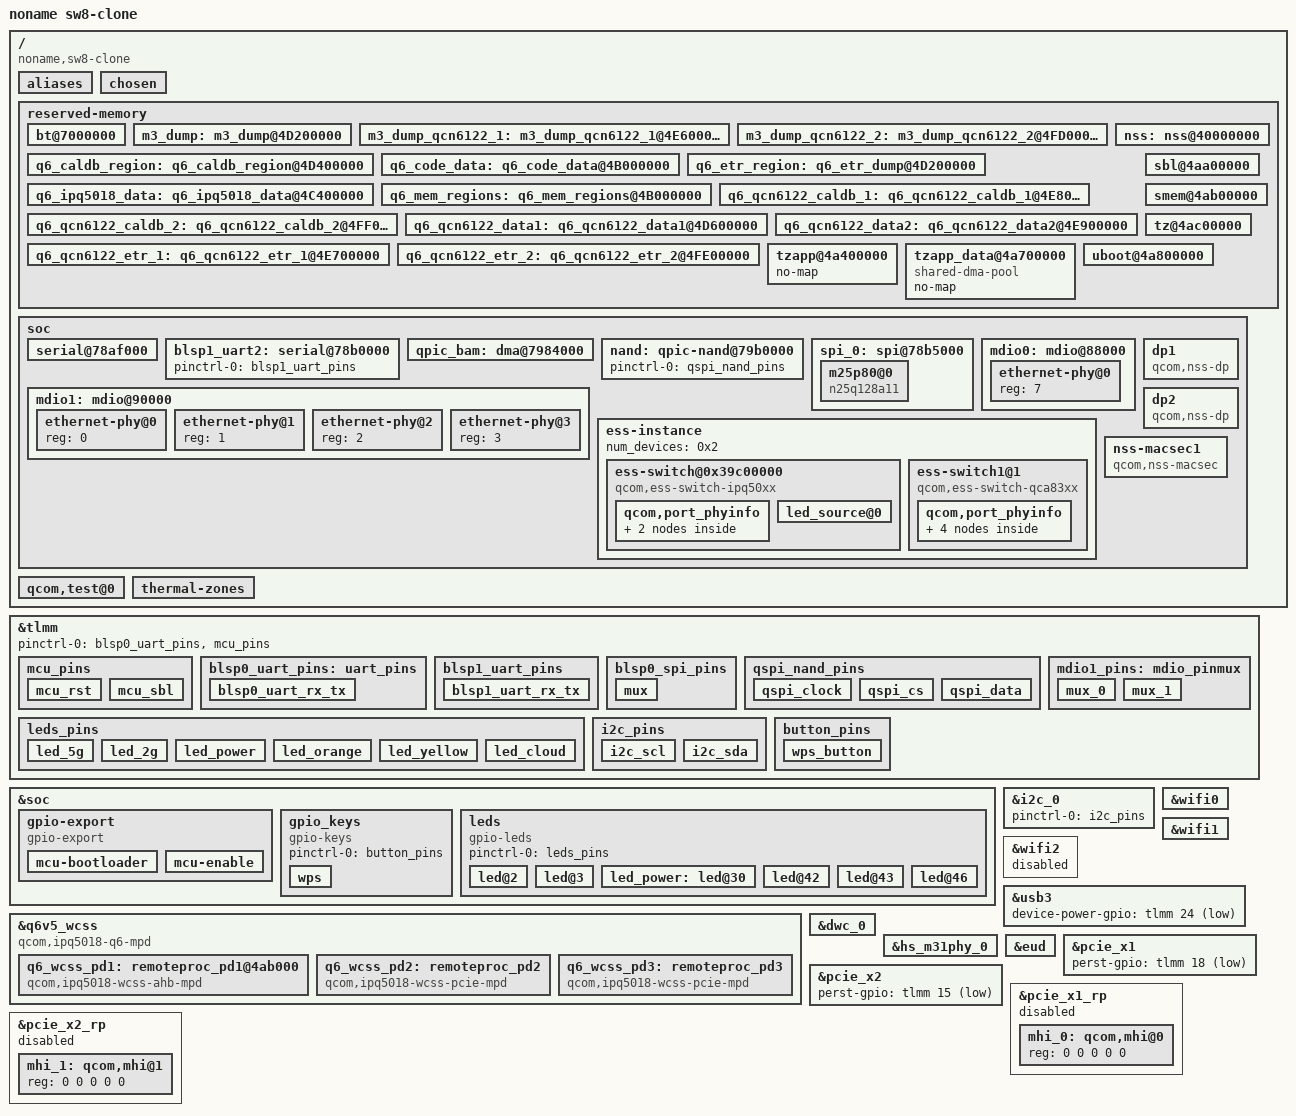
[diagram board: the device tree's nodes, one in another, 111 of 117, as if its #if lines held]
/dts-v1/;

#include "ipq5018.dtsi"
#include <dt-bindings/input/input.h>

/ {
	#address-cells = <0x2>;
	#size-cells = <0x2>;
	model = "noname sw8-clone";
	compatible = "noname,sw8-clone", "qcom,ipq5018-mp03.5", "qcom,ipq5018";
	interrupt-parent = <&intc>;

	aliases {
		sdhc1 = &sdhc_1; /* SDC1 eMMC slot */
		serial0 = &blsp1_uart1;
		serial1 = &blsp1_uart2;
		ethernet0 = "/soc/dp1";
		ethernet1 = "/soc/dp2";

		led-boot = &led_power;
		led-failsafe = &led_power;
		led-running = &led_power;
		led-upgrade = &led_power;
	};

	chosen {
		bootargs = "console=ttyMSM0,115200,n8 rw init=/init";
		bootargs-append = " root=/dev/ubiblock0_1 swiotlb=1 coherent_pool=2M";
		stdout-path = "serial0";
	};

	reserved-memory {
		#address-cells = <0x02>;
		#size-cells = <0x02>;
		ranges;

		bt@7000000 {
			no-map;
			reg = <0x00 0x7000000 0x00 0x58000>;
		};

		m3_dump: m3_dump@4D200000 {
			no-map;
			reg = <0x00 0x4d200000 0x00 0x100000>;
		};

		m3_dump_qcn6122_1: m3_dump_qcn6122_1@4E600000 {
			no-map;
			reg = <0x00 0x4e600000 0x00 0x100000>;
		};

		m3_dump_qcn6122_2: m3_dump_qcn6122_2@4FD00000 {
			no-map;
			reg = <0x00 0x4fd00000 0x00 0x100000>;
		};

		nss: nss@40000000 {
			no-map;
			reg = <0x00 0x40000000 0x00 0x1000000>;
		};

		q6_caldb_region: q6_caldb_region@4D400000 {
			no-map;
			reg = <0x00 0x4d400000 0x00 0x200000>;
		};

		q6_code_data: q6_code_data@4B000000 {
			no-map;
			reg = <0x00 0x4b000000 0x00 0x60000>;
		};

		q6_etr_region: q6_etr_dump@4D200000 {
			no-map;
			reg = <0x00 0x4d200000 0x00 0x100000>;
		};

		q6_ipq5018_data: q6_ipq5018_data@4C400000 {
			no-map;
			reg = <0x00 0x4c400000 0x00 0xd00000>;
		};

		q6_mem_regions: q6_mem_regions@4B000000 {
			no-map;
			reg = <0x00 0x4b000000 0x00 0x3400000>;
		};

		q6_qcn6122_caldb_1: q6_qcn6122_caldb_1@4E800000 {
			linux,phandle = <0x1c>;
			no-map;
			phandle = <0x1c>;
			reg = <0x00 0x4e800000 0x00 0x500000>;
		};

		q6_qcn6122_caldb_2: q6_qcn6122_caldb_2@4FF00000 {
			no-map;
			reg = <0x00 0x4ff00000 0x00 0x500000>;
		};

		q6_qcn6122_data1: q6_qcn6122_data1@4D600000 {
			linux,phandle = <0x19>;
			no-map;
			phandle = <0x19>;
			reg = <0x00 0x4d600000 0x00 0x1000000>;
		};

		q6_qcn6122_data2: q6_qcn6122_data2@4E900000 {
			no-map;
			reg = <0x00 0x4ed00000 0x00 0x1000000>;
		};

		q6_qcn6122_etr_1: q6_qcn6122_etr_1@4E700000 {
			linux,phandle = <0x1b>;
			no-map;
			phandle = <0x1b>;
			reg = <0x00 0x4e700000 0x00 0x100000>;
		};

		q6_qcn6122_etr_2: q6_qcn6122_etr_2@4FE00000 {
			no-map;
			reg = <0x00 0x4fe00000 0x00 0x100000>;
		};

		sbl@4aa00000 {
			no-map;
			reg = <0x00 0x4aa00000 0x00 0x100000>;
		};

		smem@4ab00000 {
			no-map;
			reg = <0x00 0x4ab00000 0x00 0x100000>;
		};

		tz@4ac00000 {
			no-map;
			reg = <0x00 0x4ac00000 0x00 0x400000>;
		};

		tzapp@4a400000 {
			no-map;
		};

		tzapp_data@4a700000 {
			compatible = "shared-dma-pool";
			no-map;
		};

		uboot@4a800000 {
			no-map;
			reg = <0x00 0x4a800000 0x00 0x200000>;
		};
	};

	soc {
		serial@78af000 {
			status = "ok";
		};

		blsp1_uart2: serial@78b0000 {
			pinctrl-0 = <&blsp1_uart_pins>;
			pinctrl-names = "default";
			status = "ok";
		};

		qpic_bam: dma@7984000{
			status = "ok";
		};

		nand: qpic-nand@79b0000 {
			pinctrl-0 = <&qspi_nand_pins>;
			pinctrl-names = "default";
			status = "ok";
		};

		spi_0: spi@78b5000 { /* BLSP1 QUP0 */
			pinctrl-0 = <&blsp0_spi_pins>;
			pinctrl-names = "default";
			cs-select = <0>;
			status = "ok";

			m25p80@0 {
				#address-cells = <1>;
				#size-cells = <1>;
				reg = <0>;
				compatible = "n25q128a11";
				linux,modalias = "m25p80", "n25q128a11";
				spi-max-frequency = <50000000>;
				use-default-sizes;
			};
		};

		mdio0: mdio@88000 {
			status = "ok";

			ethernet-phy@0 {
				reg = <7>;
			};
		};

		mdio1: mdio@90000 {
			status = "ok";
			pinctrl-0 = <&mdio1_pins>;
			pinctrl-names = "default";
			phy-reset-gpio = <&tlmm 39 0>;
			ethernet-phy@0 {
				reg = <0>;
			};

			ethernet-phy@1 {
				reg = <1>;
			};

			ethernet-phy@2 {
				reg = <2>;
			};

			ethernet-phy@3 {
				reg = <3>;
			};
		};

		ess-instance {
			num_devices = <0x2>;
			ess-switch@0x39c00000 {
				compatible = "qcom,ess-switch-ipq50xx";
				device_id = <0>;
				switch_mac_mode = <0xf>; /* mac mode for uniphy instance*/
				cmnblk_clk = "internal_96MHz"; /* cmnblk clk*/
				qcom,port_phyinfo {
					port@0 {
						port_id = <1>;
						phy_address = <7>;
					};
					port@1 {
						port_id = <2>;
						forced-speed = <1000>;
						forced-duplex = <1>;
					};
				};
				led_source@0 {
					source = <0>;
					mode = "normal";
					speed = "all";
					blink_en = "enable";
					active = "high";
				};
			};
			ess-switch1@1 {
				compatible = "qcom,ess-switch-qca83xx";
				device_id = <1>;
				switch_access_mode = "mdio";
				mdio-bus = <&mdio1>;
				reset_gpio = <&tlmm 0x27 0>;
				switch_cpu_bmp = <0x40>;  /* cpu port bitmap */
				switch_lan_bmp = <0x1e>; /* lan port bitmap */
				switch_wan_bmp = <0x0>;  /* wan port bitmap */
				qca,ar8327-initvals = <
						0x00004 0x7600000   /* PAD0_MODE */
						0x00008 0x1000000   /* PAD5_MODE */
						0x0000c 0x80	/* PAD6_MODE */
						0x00010 0x2613a0    /* PORT6 FORCE MODE*/
						0x000e4 0xaa545     /* MAC_POWER_SEL */
						0x000e0 0xc74164de  /* SGMII_CTRL */
						0x0007c 0x4e	/* PORT0_STATUS */
						0x00094 0x4e	/* PORT6_STATUS */
				>;
				qcom,port_phyinfo {
					port@0 {
						port_id = <1>;
						phy_address = <0>;
					};
					port@1 {
						port_id = <2>;
						phy_address = <1>;
					};
					port@2 {
						port_id = <3>;
						phy_address = <2>;
					};
					port@3 {
						port_id = <4>;
						phy_address = <3>;
					};
				};
			};
		};

		dp1 {
			device_type = "network";
			compatible = "qcom,nss-dp";
			clocks = <&gcc GCC_SNOC_GMAC0_AXI_CLK>;
			clock-names = "nss-snoc-gmac-axi-clk";
			qcom,id = <1>;
			reg = <0x39C00000 0x10000>;
			interrupts = <GIC_SPI 101 IRQ_TYPE_LEVEL_HIGH>;
			qcom,mactype = <2>;
			qcom,link-poll = <1>;
			qcom,phy-mdio-addr = <7>;
			mdio-bus = <&mdio0>;
			local-mac-address = [000000000000];
			phy-mode = "sgmii";
			qcom,rx-page-mode = <0>;
		};

		dp2 {
			device_type = "network";
			compatible = "qcom,nss-dp";
			clocks = <&gcc GCC_SNOC_GMAC1_AXI_CLK>;
			clock-names = "nss-snoc-gmac-axi-clk";
			qcom,id = <2>;
			reg = <0x39D00000 0x10000>;
			interrupts = <GIC_SPI 109 IRQ_TYPE_LEVEL_HIGH>;
			qcom,mactype = <2>;
			local-mac-address = [000000000000];
			phy-mode = "sgmii";
			qcom,rx-page-mode = <0>;
		};

		nss-macsec1 {
			compatible = "qcom,nss-macsec";
			phy_addr = <0x1c>;
			mdiobus = <&mdio1>;
		};
	};

	qcom,test@0 {
		status = "ok";
	};

	thermal-zones {
		status = "ok";
	};
};

&tlmm {
	pinctrl-0 = <&blsp0_uart_pins &mcu_pins>;
	pinctrl-names = "default";

	mcu_pins: mcu_pins {
		mcu_rst {
			pins = "gpio31";
			function = "gpio";
			drive-strength = <8>;
			bias-disable;
			output-low;
		};

		mcu_sbl {
			pins = "gpio35";
			function = "gpio";
			drive-strength = <8>;
			bias-disable;
			output-low;
		};
	};

	blsp0_uart_pins: uart_pins {
		blsp0_uart_rx_tx {
			pins = "gpio20", "gpio21";
			function = "blsp0_uart0";
			bias-disable;
		};
	};

	blsp1_uart_pins: blsp1_uart_pins {
		blsp1_uart_rx_tx {
			pins = "gpio23", "gpio25", "gpio24", "gpio26";
			function = "blsp1_uart2";
			bias-disable;
		};
	};

	blsp0_spi_pins: blsp0_spi_pins {
		mux {
			pins = "gpio10", "gpio11", "gpio12", "gpio13";
			function = "blsp0_spi";
			drive-strength = <2>;
			bias-disable;
		};
	};

	qspi_nand_pins: qspi_nand_pins {
		qspi_clock {
			pins = "gpio9";
			function = "qspi_clk";
			drive-strength = <8>;
			bias-disable;
		};

		qspi_cs {
			pins = "gpio8";
			function = "qspi_cs";
			drive-strength = <8>;
			bias-disable;
		};

		qspi_data {
			pins = "gpio4", "gpio5", "gpio6", "gpio7";
			function = "qspi_data";
			drive-strength = <8>;
			bias-disable;
		};
	};

	mdio1_pins: mdio_pinmux {
		mux_0 {
			pins = "gpio36";
			function = "mdc";
			drive-strength = <8>;
			bias-pull-up;
		};

		mux_1 {
			pins = "gpio37";
			function = "mdio";
			drive-strength = <8>;
			bias-pull-up;
		};
	};

	leds_pins: leds_pins {
		led_5g {
			pins = "gpio2";
			function = "gpio";
			drive-strength = <8>;
			bias-pull-down;
		};
		led_2g {
			pins = "gpio3";
			function = "gpio";
			drive-strength = <8>;
			bias-pull-down;
		};
		led_power {
			pins = "gpio30";
			function = "gpio";
			drive-strength = <8>;
			bias-pull-down;
		};
		led_orange {
			pins = "gpio42";
			function = "gpio";
			drive-strength = <8>;
			bias-pull-down;
		};
		led_yellow {
			pins = "gpio43";
			function = "gpio";
			drive-strength = <8>;
			bias-pull-down;
		};
		led_cloud {
			pins = "gpio46";
			function = "gpio";
			drive-strength = <8>;
			bias-pull-down;
		};
	};

	i2c_pins: i2c_pins {
		i2c_scl {
			pins = "gpio33";
			function = "blsp2_i2c0";
			drive-strength = <8>;
			bias-pull-up;
		};

		i2c_sda {
			pins = "gpio34";
			function = "blsp2_i2c0";
			drive-strength = <8>;
			bias-pull-up;
		};
	};

	button_pins: button_pins {
		wps_button {
			pins = "gpio38";
			function = "gpio";
			drive-strength = <8>;
			bias-pull-up;
		};
	};
};

&soc {
	gpio-export {
		compatible = "gpio-export";
		#size-cells = <0>;

		mcu-bootloader {
			gpio-export,name = "mcu-bootloader";
			gpio-export,output = <0>;
			gpios = <&tlmm 35 GPIO_ACTIVE_LOW>;
		};

		mcu-enable {
			gpio-export,name = "mcu-enable";
			gpio-export,output = <0>;
			gpios = <&tlmm 31 GPIO_ACTIVE_HIGH>;
		};
	};

	gpio_keys {
		compatible = "gpio-keys";
		pinctrl-0 = <&button_pins>;
		pinctrl-names = "default";

		wps {
			label = "reset";
			linux,code = <KEY_RESTART>;
			gpios = <&tlmm 32 GPIO_ACTIVE_LOW>;
			linux,input-type = <1>;
			debounce-interval = <60>;
		};
	};

	leds {
		compatible = "gpio-leds";
		pinctrl-0 = <&leds_pins>;
		pinctrl-names = "default";

		led@2 {
			label = "green:wifi5";
			gpios = <&tlmm 2 GPIO_ACTIVE_HIGH>;
			default-state = "off";
		};
		led@3 {
			label = "green:wifi2";
			gpios = <&tlmm 3 GPIO_ACTIVE_HIGH>;
			default-state = "off";
		};
		led_power: led@30 {
			label = "green:power";
			gpios = <&tlmm 30 GPIO_ACTIVE_HIGH>;
			default-state = "on";
		};
		led@42 {
			label = "orange:uplink";
			gpios = <&tlmm 42 GPIO_ACTIVE_HIGH>;
			default-state = "off";
		};
		led@43 {
			label = "yellow:uplink";
			gpios = <&tlmm 43 GPIO_ACTIVE_HIGH>;
			default-state = "off";
		};
		led@46 {
			label = "green:cloud";
			gpios = <&tlmm 46 GPIO_ACTIVE_HIGH>;
			default-state = "off";
		};
	};
};

&q6v5_wcss {
	compatible = "qcom,ipq5018-q6-mpd";
	#address-cells = <1>;
	#size-cells = <1>;
	ranges;
	firmware = "IPQ5018/q6_fw.mdt";
	reg = <0x0cd00000 0x4040>,
		<0x1938000 0x8>,
		<0x193d204 0x4>;
	reg-names = "qdsp6",
			"tcsr-msip",
			"tcsr-q6";
	resets = <&gcc GCC_WCSSAON_RESET>,
			<&gcc GCC_WCSS_Q6_BCR>;

	reset-names = "wcss_aon_reset",
			"wcss_q6_reset";

	clocks = <&gcc GCC_Q6_AXIS_CLK>,
		<&gcc GCC_WCSS_ECAHB_CLK>,
		<&gcc GCC_Q6_AXIM_CLK>,
		<&gcc GCC_Q6_AXIM2_CLK>,
		<&gcc GCC_Q6_AHB_CLK>,
		<&gcc GCC_Q6_AHB_S_CLK>,
		<&gcc GCC_WCSS_AXI_S_CLK>;
	clock-names = "gcc_q6_axis_clk",
		"gcc_wcss_ecahb_clk",
		"gcc_q6_axim_clk",
		"gcc_q6_axim2_clk",
		"gcc_q6_ahb_clk",
		"gcc_q6_ahb_s_clk",
		"gcc_wcss_axi_s_clk";

		memory-region = <&q6_mem_regions>, <&q6_etr_region>, <&q6_caldb_region>;

	qcom,rproc = <&q6v5_wcss>;
	qcom,bootargs_smem = <507>;
	boot-args = <0x1 0x4 0x3 0x0F 0x0 0x0>,
			<0x2 0x4 0x2 0x12 0x0 0x0>;
	status = "ok";
	q6_wcss_pd1: remoteproc_pd1@4ab000 {
		compatible = "qcom,ipq5018-wcss-ahb-mpd";
		reg = <0x4ab000 0x20>;
		reg-names = "rmb";
		firmware = "IPQ5018/q6_fw.mdt";
		m3_firmware = "IPQ5018/m3_fw.mdt";
		interrupts-extended = <&wcss_smp2p_in 8 0>,
					<&wcss_smp2p_in 9 0>,
					<&wcss_smp2p_in 12 0>,
					<&wcss_smp2p_in 11 0>;
		interrupt-names = "fatal",
					"ready",
					"spawn-ack",
					"stop-ack";

		resets = <&gcc GCC_WCSSAON_RESET>,
				<&gcc GCC_WCSS_BCR>,
				<&gcc GCC_CE_BCR>;
		reset-names = "wcss_aon_reset",
				"wcss_reset",
				"ce_reset";

		clocks = <&gcc GCC_WCSS_AHB_S_CLK>,
				<&gcc GCC_WCSS_ACMT_CLK>,
				<&gcc GCC_WCSS_AXI_M_CLK>;
		clock-names = "gcc_wcss_ahb_s_clk",
					"gcc_wcss_acmt_clk",
					"gcc_wcss_axi_m_clk";

		qcom,halt-regs = <&tcsr_q6_block 0xa000 0xd000 0x0>;

		qcom,smem-states = <&wcss_smp2p_out 8>,
					<&wcss_smp2p_out 9>,
					<&wcss_smp2p_out 10>;
		qcom,smem-state-names = "shutdown",
					"stop",
					"spawn";
		memory-region = <&q6_ipq5018_data>, <&m3_dump>, <&q6_etr_region>, <&q6_caldb_region>;

	};

	q6_wcss_pd2: remoteproc_pd2 {
		compatible = "qcom,ipq5018-wcss-pcie-mpd";
		firmware = "IPQ5018/q6_fw.mdt";
		m3_firmware = "qcn6122/m3_fw.mdt";
		interrupts-extended = <&wcss_smp2p_in 16 0>,
					<&wcss_smp2p_in 17 0>,
					<&wcss_smp2p_in 20 0>,
					<&wcss_smp2p_in 19 0>;
		interrupt-names = "fatal",
					"ready",
					"spawn-ack",
					"stop-ack";

		qcom,smem-states = <&wcss_smp2p_out 16>,
					<&wcss_smp2p_out 17>,
					<&wcss_smp2p_out 18>;
		qcom,smem-state-names = "shutdown",
					"stop",
					"spawn";
	#ifdef __IPQ_MEM_PROFILE_256_MB__
		memory-region = <&q6_qcn6122_data1>, <&m3_dump_qcn6122_1>,
				<&q6_qcn6122_etr_1>;
	#else
		memory-region = <&q6_qcn6122_data1>, <&m3_dump_qcn6122_1>,
				<&q6_qcn6122_etr_1>, <&q6_qcn6122_caldb_1>;
	#endif

	};

	q6_wcss_pd3: remoteproc_pd3 {
		compatible = "qcom,ipq5018-wcss-pcie-mpd";
		firmware = "IPQ5018/q6_fw.mdt";
		interrupts-extended = <&wcss_smp2p_in 24 0>,
					<&wcss_smp2p_in 25 0>,
					<&wcss_smp2p_in 28 0>,
					<&wcss_smp2p_in 27 0>;
		interrupt-names = "fatal",
					"ready",
					"spawn-ack",
					"stop-ack";

		qcom,smem-states = <&wcss_smp2p_out 24>,
					<&wcss_smp2p_out 25>,
					<&wcss_smp2p_out 26>;
		qcom,smem-state-names = "shutdown",
					"stop",
					"spawn";
	#ifdef	__IPQ_MEM_PROFILE_256_MB__
		memory-region = <&q6_qcn6122_data2>, <&m3_dump_qcn6122_2>,
				<&q6_qcn6122_etr_2>;
	#else
		memory-region = <&q6_qcn6122_data2>, <&m3_dump_qcn6122_2>,
				<&q6_qcn6122_etr_2>, <&q6_qcn6122_caldb_2>;
	#endif
	};
};

&i2c_0 {
	pinctrl-0 = <&i2c_pins>;
	pinctrl-names = "default";
};

&wifi0 {
	/* IPQ5018 */
	qcom,multipd_arch;
	qcom,rproc = <&q6_wcss_pd1>;
	qcom,userpd-subsys-name = "q6v5_wcss_userpd1";
	qcom,tgt-mem-mode = <1>;
	qcom,board_id = <0x23>;
	memory-region = <&q6_ipq5018_data>;
	status = "ok";
};

&wifi1 {
	/* QCN6122 5G */
	qcom,multipd_arch;
	qcom,userpd-subsys-name = "q6v5_wcss_userpd2";
	qcom,rproc = <&q6_wcss_pd2>;
	qcom,tgt-mem-mode = <1>;
	qcom,board_id = <0x60>;
	memory-region = <&q6_qcn6122_data1>;
	status = "ok";
};

&wifi2 {
	/* QCN6122 6G */
	qcom,multipd_arch;
	qcom,userpd-subsys-name = "q6v5_wcss_userpd3";
	qcom,rproc = <&q6_wcss_pd3>;
	qcom,tgt-mem-mode = <1>;
	qcom,board_id = <0xb0>;
	memory-region = <&q6_qcn6122_data2>;
	status = "disabled";
};

&usb3 {
       status = "ok";
       device-power-gpio = <&tlmm 24 1>;
};

&dwc_0 {
       /delete-property/ #phy-cells;
       /delete-property/ phys;
       /delete-property/ phy-names;
};

&hs_m31phy_0 {
       status = "ok";
};

&eud {
	status = "ok";
};

&pcie_x1 {
	perst-gpio = <&tlmm 18 GPIO_ACTIVE_LOW>;
};

&pcie_x2 {
	perst-gpio = <&tlmm 15 GPIO_ACTIVE_LOW>;
};

&pcie_x1_rp {
	status = "disabled";

	mhi_0: qcom,mhi@0 {
		reg = <0 0 0 0 0 >;
	};
};

&pcie_x2_rp {
	status = "disabled";

	mhi_1: qcom,mhi@1 {
		reg = <0 0 0 0 0 >;

	};
};
